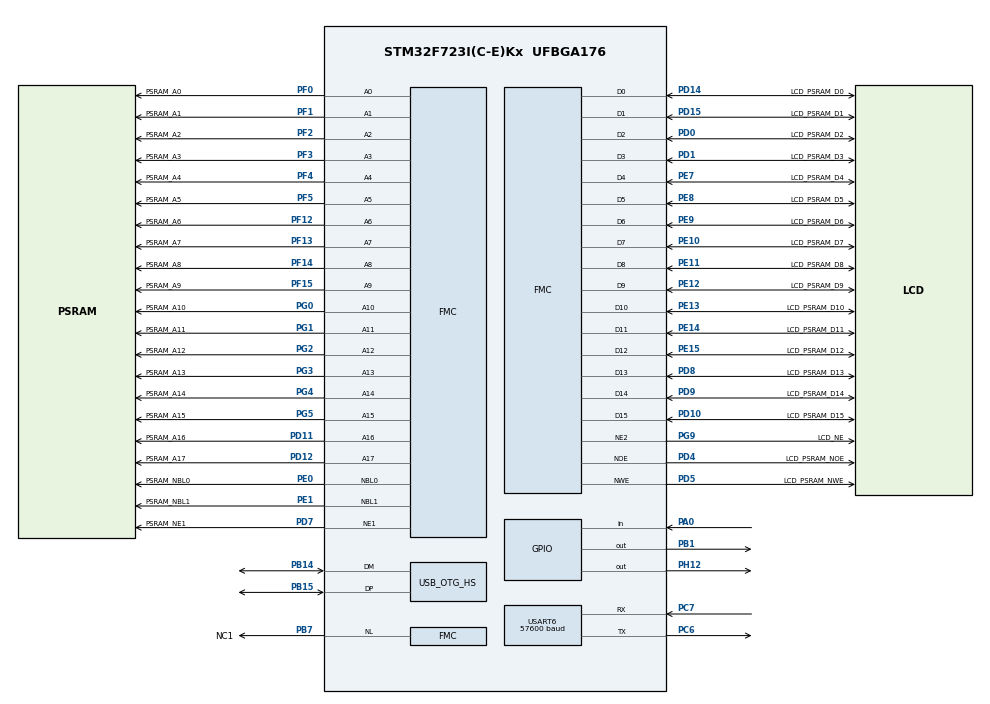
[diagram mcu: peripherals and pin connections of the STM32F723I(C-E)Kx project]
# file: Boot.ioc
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CORTEX_M7.CPU_ICache=Disabled
CORTEX_M7.PREFETCH_ENABLE=0
FMC.WriteOperation1=FMC_WRITE_OPERATION_ENABLE
Mcu.Family=STM32F7
Mcu.Name=STM32F723I(C-E)Kx
Mcu.Package=UFBGA176
NVIC.PriorityGroup=NVIC_PRIORITYGROUP_4
PA0-WKUP.Signal=GPIO_Input
PB1.Signal=GPIO_Output
PB14.Mode=Internal_Phy_Host
PB14.Signal=USB_OTG_HS_DM
PB15.Mode=Internal_Phy_Host
PB15.Signal=USB_OTG_HS_DP
PB7.GPIO_Label=NC1
PB7.Signal=FMC_NL
PC6.Mode=Asynchronous
PC6.Signal=USART6_TX
PC7.Mode=Asynchronous
PC7.Signal=USART6_RX
PD0.GPIO_Label=LCD_PSRAM_D2
PD0.Signal=FMC_D2_DA2
PD1.GPIO_Label=LCD_PSRAM_D3
PD1.Signal=FMC_D3_DA3
PD10.GPIO_Label=LCD_PSRAM_D15
PD10.Signal=FMC_D15_DA15
PD11.GPIO_Label=PSRAM_A16
PD11.Signal=FMC_A16_CLE
PD12.GPIO_Label=PSRAM_A17
PD12.Signal=FMC_A17_ALE
PD14.GPIO_Label=LCD_PSRAM_D0
PD14.Signal=FMC_D0_DA0
PD15.GPIO_Label=LCD_PSRAM_D1
PD15.Signal=FMC_D1_DA1
PD4.GPIO_Label=LCD_PSRAM_NOE
PD4.Signal=FMC_NOE
PD5.GPIO_Label=LCD_PSRAM_NWE
PD5.Signal=FMC_NWE
PD7.GPIO_Label=PSRAM_NE1
PD7.Mode=NorPsramChipSelect1_1
PD7.Signal=FMC_NE1
PD8.GPIO_Label=LCD_PSRAM_D13
PD8.Signal=FMC_D13_DA13
PD9.GPIO_Label=LCD_PSRAM_D14
PD9.Signal=FMC_D14_DA14
PE0.GPIO_Label=PSRAM_NBL0
PE0.Signal=FMC_NBL0
PE1.GPIO_Label=PSRAM_NBL1
PE1.Signal=FMC_NBL1
PE10.GPIO_Label=LCD_PSRAM_D7
PE10.Signal=FMC_D7_DA7
PE11.GPIO_Label=LCD_PSRAM_D8
PE11.Signal=FMC_D8_DA8
PE12.GPIO_Label=LCD_PSRAM_D9
PE12.Signal=FMC_D9_DA9
PE13.GPIO_Label=LCD_PSRAM_D10
PE13.Signal=FMC_D10_DA10
PE14.GPIO_Label=LCD_PSRAM_D11
PE14.Signal=FMC_D11_DA11
PE15.GPIO_Label=LCD_PSRAM_D12
PE15.Signal=FMC_D12_DA12
PE7.GPIO_Label=LCD_PSRAM_D4
PE7.Signal=FMC_D4_DA4
PE8.GPIO_Label=LCD_PSRAM_D5
PE8.Signal=FMC_D5_DA5
PE9.GPIO_Label=LCD_PSRAM_D6
PE9.Signal=FMC_D6_DA6
PF0.GPIO_Label=PSRAM_A0
PF0.Signal=FMC_A0
PF1.GPIO_Label=PSRAM_A1
PF1.Signal=FMC_A1
PF12.GPIO_Label=PSRAM_A6
PF12.Signal=FMC_A6
PF13.GPIO_Label=PSRAM_A7
PF13.Signal=FMC_A7
PF14.GPIO_Label=PSRAM_A8
PF14.Signal=FMC_A8
PF15.GPIO_Label=PSRAM_A9
PF15.Signal=FMC_A9
PF2.GPIO_Label=PSRAM_A2
PF2.Signal=FMC_A2
PF3.GPIO_Label=PSRAM_A3
PF3.Signal=FMC_A3
PF4.GPIO_Label=PSRAM_A4
PF4.Signal=FMC_A4
PF5.GPIO_Label=PSRAM_A5
PF5.Signal=FMC_A5
PG0.GPIO_Label=PSRAM_A10
PG0.Signal=FMC_A10
PG1.GPIO_Label=PSRAM_A11
PG1.Signal=FMC_A11
PG2.GPIO_Label=PSRAM_A12
PG2.Signal=FMC_A12
PG3.GPIO_Label=PSRAM_A13
PG3.Signal=FMC_A13
PG4.GPIO_Label=PSRAM_A14
PG4.Signal=FMC_A14_BA0
PG5.GPIO_Label=PSRAM_A15
PG5.Signal=FMC_A15_BA1
PG9.GPIO_Label=LCD_NE
PG9.Mode=NorPsramChipSelect2_2
PG9.Signal=FMC_NE2
PH0-OSC_IN.Mode=HSE-External-Clock-Source
PH0-OSC_IN.Signal=RCC_OSC_IN
PH1-OSC_OUT.Mode=HSE-External-Clock-Source
PH1-OSC_OUT.Signal=RCC_OSC_OUT
PH12.PinState=GPIO_PIN_SET
PH12.Signal=GPIO_Output
ProjectManager.HeapSize=0x200
ProjectManager.StackSize=0x1000
ProjectManager.TargetToolchain=STM32CubeIDE
RCC.AHBFreq_Value=216000000
RCC.APB1CLKDivider=RCC_HCLK_DIV4
RCC.APB1Freq_Value=54000000
RCC.APB1TimFreq_Value=108000000
RCC.APB2CLKDivider=RCC_HCLK_DIV2
RCC.APB2Freq_Value=108000000
RCC.APB2TimFreq_Value=216000000
RCC.CortexFreq_Value=216000000
RCC.HCLKFreq_Value=216000000
RCC.HSE_VALUE=25000000
RCC.HSI_VALUE=16000000
RCC.LSE_VALUE=32768
RCC.PLLM=25
RCC.PLLN=432
RCC.PLLQ=9
RCC.SYSCLKFreq_VALUE=216000000
RCC.SYSCLKSource=RCC_SYSCLKSOURCE_PLLCLK
RCC.USBFreq_Value=48000000
RCC.VCOOutputFreq_Value=432000000
REXTPHYHS.Mode=Internal_Phy_Host
REXTPHYHS.Signal=USB_OTG_HS_REXTPHYHS
SH.FMC_A0.0=FMC_A0,18b-a1
SH.FMC_A0.1=FMC_A0,A0_2
SH.FMC_A1.0=FMC_A1,18b-a1
SH.FMC_A10.0=FMC_A10,18b-a1
SH.FMC_A11.0=FMC_A11,18b-a1
SH.FMC_A12.0=FMC_A12,18b-a1
SH.FMC_A13.0=FMC_A13,18b-a1
SH.FMC_A14_BA0.0=FMC_A14,18b-a1
SH.FMC_A15_BA1.0=FMC_A15,18b-a1
SH.FMC_A16_CLE.0=FMC_A16,18b-a1
SH.FMC_A17_ALE.0=FMC_A17,18b-a1
SH.FMC_A2.0=FMC_A2,18b-a1
SH.FMC_A3.0=FMC_A3,18b-a1
SH.FMC_A4.0=FMC_A4,18b-a1
SH.FMC_A5.0=FMC_A5,18b-a1
SH.FMC_A6.0=FMC_A6,18b-a1
SH.FMC_A7.0=FMC_A7,18b-a1
SH.FMC_A8.0=FMC_A8,18b-a1
SH.FMC_A9.0=FMC_A9,18b-a1
SH.FMC_D0_DA0.0=FMC_D0,16b-d1
SH.FMC_D0_DA0.1=FMC_D0,16b-d2
SH.FMC_D10_DA10.0=FMC_D10,16b-d1
SH.FMC_D10_DA10.1=FMC_D10,16b-d2
SH.FMC_D11_DA11.0=FMC_D11,16b-d1
SH.FMC_D11_DA11.1=FMC_D11,16b-d2
SH.FMC_D12_DA12.0=FMC_D12,16b-d1
SH.FMC_D12_DA12.1=FMC_D12,16b-d2
SH.FMC_D13_DA13.0=FMC_D13,16b-d1
SH.FMC_D13_DA13.1=FMC_D13,16b-d2
SH.FMC_D14_DA14.0=FMC_D14,16b-d1
SH.FMC_D14_DA14.1=FMC_D14,16b-d2
SH.FMC_D15_DA15.0=FMC_D15,16b-d1
SH.FMC_D15_DA15.1=FMC_D15,16b-d2
SH.FMC_D1_DA1.0=FMC_D1,16b-d1
SH.FMC_D1_DA1.1=FMC_D1,16b-d2
SH.FMC_D2_DA2.0=FMC_D2,16b-d1
SH.FMC_D2_DA2.1=FMC_D2,16b-d2
SH.FMC_D3_DA3.0=FMC_D3,16b-d1
SH.FMC_D3_DA3.1=FMC_D3,16b-d2
SH.FMC_D4_DA4.0=FMC_D4,16b-d1
SH.FMC_D4_DA4.1=FMC_D4,16b-d2
SH.FMC_D5_DA5.0=FMC_D5,16b-d1
SH.FMC_D5_DA5.1=FMC_D5,16b-d2
SH.FMC_D6_DA6.0=FMC_D6,16b-d1
SH.FMC_D6_DA6.1=FMC_D6,16b-d2
SH.FMC_D7_DA7.0=FMC_D7,16b-d1
SH.FMC_D7_DA7.1=FMC_D7,16b-d2
SH.FMC_D8_DA8.0=FMC_D8,16b-d1
SH.FMC_D8_DA8.1=FMC_D8,16b-d2
SH.FMC_D9_DA9.0=FMC_D9,16b-d1
SH.FMC_D9_DA9.1=FMC_D9,16b-d2
SH.FMC_NBL0.0=FMC_NBL0,2ByteEnable1
SH.FMC_NBL1.0=FMC_NBL1,2ByteEnable1
SH.FMC_NL.0=FMC_NL,AddressValid1
SH.FMC_NOE.0=FMC_NOE,Psram1
SH.FMC_NOE.1=FMC_NOE,Lcd2
SH.FMC_NWE.0=FMC_NWE,Psram1
SH.FMC_NWE.1=FMC_NWE,Lcd2
USART6.BaudRate=57600
USART6.VirtualMode-Asynchronous=VM_ASYNC
USB_OTG_HS.VirtualMode=Int_Phy_Host
board=STM32F723E-DISCO

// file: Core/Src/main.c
/* USER CODE BEGIN Header */
/**
  ******************************************************************************
  * @file           : main.c
  * @brief          : Main program body
  ******************************************************************************
  * @attention
  *
  * Copyright (c) 2026 STMicroelectronics.
  * All rights reserved.
  *
  * This software is licensed under terms that can be found in the LICENSE file
  * in the root directory of this software component.
  * If no LICENSE file comes with this software, it is provided AS-IS.
  *
  ******************************************************************************
  */
/* USER CODE END Header */
#include "main.h"

/* USER CODE BEGIN Includes */
#include "app.h"
/* USER CODE END Includes */

HCD_HandleTypeDef hhcd_USB_OTG_HS;

SRAM_HandleTypeDef hsram1;
SRAM_HandleTypeDef hsram2;

void SystemClock_Config(void);
static void MX_GPIO_Init(void);
static void MX_USART6_UART_Init(void);

int main(void)
{

  /* MCU Configuration--------------------------------------------------------*/

  /* Reset of all peripherals, Initializes the Flash interface and the Systick. */
  HAL_Init();

  /* Configure the system clock */
  SystemClock_Config();

  /* Initialize all configured peripherals */
  MX_GPIO_Init();
  MX_USART6_UART_Init();
  /* USER CODE BEGIN 2 */
  /* Initialize the USB HS clock and GPIO pins. */
  HCD_HandleTypeDef usbHandle;
  usbHandle.Instance = USB_OTG_HS;
  HAL_HCD_MspInit(&usbHandle);
  /* Initialize the bootloader application. */
  AppInit();
  /* USER CODE END 2 */

  /* Infinite loop */
  /* USER CODE BEGIN WHILE */
  while (1)
  {
    /* Run the bootloader application. */
    AppTask();
    /* USER CODE END WHILE */

  }
}

void SystemClock_Config(void)
{
  LL_FLASH_SetLatency(LL_FLASH_LATENCY_7);
  while(LL_FLASH_GetLatency()!= LL_FLASH_LATENCY_7)
  {
  }
  LL_PWR_SetRegulVoltageScaling(LL_PWR_REGU_VOLTAGE_SCALE1);
  LL_PWR_EnableOverDriveMode();
  LL_RCC_HSE_EnableBypass();
  LL_RCC_HSE_Enable();

   /* Wait till HSE is ready */
  while(LL_RCC_HSE_IsReady() != 1)
  {

  }
  LL_RCC_PLL_ConfigDomain_SYS(LL_RCC_PLLSOURCE_HSE, LL_RCC_PLLM_DIV_25, 432, LL_RCC_PLLP_DIV_2);
  LL_RCC_PLL_ConfigDomain_48M(LL_RCC_PLLSOURCE_HSE, LL_RCC_PLLM_DIV_25, 432, LL_RCC_PLLQ_DIV_9);
  LL_RCC_PLL_Enable();

   /* Wait till PLL is ready */
  while(LL_RCC_PLL_IsReady() != 1)
  {

  }
  while (LL_PWR_IsActiveFlag_VOS() == 0)
  {
  }
  LL_RCC_SetAHBPrescaler(LL_RCC_SYSCLK_DIV_1);
  LL_RCC_SetAPB1Prescaler(LL_RCC_APB1_DIV_4);
  LL_RCC_SetAPB2Prescaler(LL_RCC_APB2_DIV_2);
  LL_RCC_SetSysClkSource(LL_RCC_SYS_CLKSOURCE_PLL);

   /* Wait till System clock is ready */
  while(LL_RCC_GetSysClkSource() != LL_RCC_SYS_CLKSOURCE_STATUS_PLL)
  {

  }
  LL_SetSystemCoreClock(216000000);

   /* Update the time base */
  if (HAL_InitTick (TICK_INT_PRIORITY) != HAL_OK)
  {
    Error_Handler();
  }

   /* Set Timers Clock Prescalers */
  LL_RCC_SetTIMPrescaler(LL_RCC_TIM_PRESCALER_TWICE);
}

static void MX_USART6_UART_Init(void)
{

  LL_USART_InitTypeDef USART_InitStruct = {0};

  LL_GPIO_InitTypeDef GPIO_InitStruct = {0};

  LL_RCC_SetUSARTClockSource(LL_RCC_USART6_CLKSOURCE_PCLK2);

  /* Peripheral clock enable */
  LL_APB2_GRP1_EnableClock(LL_APB2_GRP1_PERIPH_USART6);

  LL_AHB1_GRP1_EnableClock(LL_AHB1_GRP1_PERIPH_GPIOC);
  /**USART6 GPIO Configuration
  PC7   ------> USART6_RX
  PC6   ------> USART6_TX
  */
  GPIO_InitStruct.Pin = LL_GPIO_PIN_7;
  GPIO_InitStruct.Mode = LL_GPIO_MODE_ALTERNATE;
  GPIO_InitStruct.Speed = LL_GPIO_SPEED_FREQ_VERY_HIGH;
  GPIO_InitStruct.OutputType = LL_GPIO_OUTPUT_PUSHPULL;
  GPIO_InitStruct.Pull = LL_GPIO_PULL_NO;
  GPIO_InitStruct.Alternate = LL_GPIO_AF_8;
  LL_GPIO_Init(GPIOC, &GPIO_InitStruct);

  GPIO_InitStruct.Pin = LL_GPIO_PIN_6;
  GPIO_InitStruct.Mode = LL_GPIO_MODE_ALTERNATE;
  GPIO_InitStruct.Speed = LL_GPIO_SPEED_FREQ_VERY_HIGH;
  GPIO_InitStruct.OutputType = LL_GPIO_OUTPUT_PUSHPULL;
  GPIO_InitStruct.Pull = LL_GPIO_PULL_NO;
  GPIO_InitStruct.Alternate = LL_GPIO_AF_8;
  LL_GPIO_Init(GPIOC, &GPIO_InitStruct);

  /* USER CODE BEGIN USART6_Init 1 */
  /* Note that the USART initialization that follows here is don't care. It is
   * reconfigured upon bootloader initialization with function Rs232Init().
   */
  /* USER CODE END USART6_Init 1 */
  USART_InitStruct.BaudRate = 57600;
  USART_InitStruct.DataWidth = LL_USART_DATAWIDTH_8B;
  USART_InitStruct.StopBits = LL_USART_STOPBITS_1;
  USART_InitStruct.Parity = LL_USART_PARITY_NONE;
  USART_InitStruct.TransferDirection = LL_USART_DIRECTION_TX_RX;
  USART_InitStruct.HardwareFlowControl = LL_USART_HWCONTROL_NONE;
  USART_InitStruct.OverSampling = LL_USART_OVERSAMPLING_16;
  LL_USART_Init(USART6, &USART_InitStruct);
  LL_USART_ConfigAsyncMode(USART6);
  LL_USART_Enable(USART6);

}

void MX_USB_OTG_HS_HCD_Init(void)
{

  /* USER CODE BEGIN USB_OTG_HS_Init 0 */
  /* Note that the USB initialization that follows here is not actually used. The USB
   * disk module handles its initialization.
   */
  /* USER CODE END USB_OTG_HS_Init 0 */

  hhcd_USB_OTG_HS.Instance = USB_OTG_HS;
  hhcd_USB_OTG_HS.Init.Host_channels = 16;
  hhcd_USB_OTG_HS.Init.speed = USB_OTG_SPEED_HIGH;
  hhcd_USB_OTG_HS.Init.dma_enable = DISABLE;
  hhcd_USB_OTG_HS.Init.phy_itface = USB_OTG_HS_EMBEDDED_PHY;
  hhcd_USB_OTG_HS.Init.Sof_enable = DISABLE;
  hhcd_USB_OTG_HS.Init.low_power_enable = DISABLE;
  hhcd_USB_OTG_HS.Init.vbus_sensing_enable = DISABLE;
  hhcd_USB_OTG_HS.Init.use_external_vbus = ENABLE;
  if (HAL_HCD_Init(&hhcd_USB_OTG_HS) != HAL_OK)
  {
    Error_Handler();
  }

}

/* FMC initialization function */
void MX_FMC_Init(void)
{

  /* USER CODE BEGIN FMC_Init 0 */
  /* Note that the FMC initialization that follows here is not actually used. The display
   * module handles its initialization.
   */
  /* USER CODE END FMC_Init 0 */

  FMC_NORSRAM_TimingTypeDef Timing = {0};

  /** Perform the SRAM1 memory initialization sequence
  */
  hsram1.Instance = FMC_NORSRAM_DEVICE;
  hsram1.Extended = FMC_NORSRAM_EXTENDED_DEVICE;
  /* hsram1.Init */
  hsram1.Init.NSBank = FMC_NORSRAM_BANK1;
  hsram1.Init.DataAddressMux = FMC_DATA_ADDRESS_MUX_DISABLE;
  hsram1.Init.MemoryType = FMC_MEMORY_TYPE_PSRAM;
  hsram1.Init.MemoryDataWidth = FMC_NORSRAM_MEM_BUS_WIDTH_16;
  hsram1.Init.BurstAccessMode = FMC_BURST_ACCESS_MODE_DISABLE;
  hsram1.Init.WaitSignalPolarity = FMC_WAIT_SIGNAL_POLARITY_LOW;
  hsram1.Init.WaitSignalActive = FMC_WAIT_TIMING_BEFORE_WS;
  hsram1.Init.WriteOperation = FMC_WRITE_OPERATION_ENABLE;
  hsram1.Init.WaitSignal = FMC_WAIT_SIGNAL_DISABLE;
  hsram1.Init.ExtendedMode = FMC_EXTENDED_MODE_DISABLE;
  hsram1.Init.AsynchronousWait = FMC_ASYNCHRONOUS_WAIT_DISABLE;
  hsram1.Init.WriteBurst = FMC_WRITE_BURST_DISABLE;
  hsram1.Init.ContinuousClock = FMC_CONTINUOUS_CLOCK_SYNC_ONLY;
  hsram1.Init.WriteFifo = FMC_WRITE_FIFO_ENABLE;
  hsram1.Init.PageSize = FMC_PAGE_SIZE_NONE;
  /* Timing */
  Timing.AddressSetupTime = 15;
  Timing.AddressHoldTime = 15;
  Timing.DataSetupTime = 255;
  Timing.BusTurnAroundDuration = 15;
  Timing.CLKDivision = 16;
  Timing.DataLatency = 17;
  Timing.AccessMode = FMC_ACCESS_MODE_A;
  /* ExtTiming */

  if (HAL_SRAM_Init(&hsram1, &Timing, NULL) != HAL_OK)
  {
    Error_Handler( );
  }

  /** Perform the SRAM2 memory initialization sequence
  */
  hsram2.Instance = FMC_NORSRAM_DEVICE;
  hsram2.Extended = FMC_NORSRAM_EXTENDED_DEVICE;
  /* hsram2.Init */
  hsram2.Init.NSBank = FMC_NORSRAM_BANK2;
  hsram2.Init.DataAddressMux = FMC_DATA_ADDRESS_MUX_DISABLE;
  hsram2.Init.MemoryType = FMC_MEMORY_TYPE_SRAM;
  hsram2.Init.MemoryDataWidth = FMC_NORSRAM_MEM_BUS_WIDTH_16;
  hsram2.Init.BurstAccessMode = FMC_BURST_ACCESS_MODE_DISABLE;
  hsram2.Init.WaitSignalPolarity = FMC_WAIT_SIGNAL_POLARITY_LOW;
  hsram2.Init.WaitSignalActive = FMC_WAIT_TIMING_BEFORE_WS;
  hsram2.Init.WriteOperation = FMC_WRITE_OPERATION_ENABLE;
  hsram2.Init.WaitSignal = FMC_WAIT_SIGNAL_DISABLE;
  hsram2.Init.ExtendedMode = FMC_EXTENDED_MODE_DISABLE;
  hsram2.Init.AsynchronousWait = FMC_ASYNCHRONOUS_WAIT_DISABLE;
  hsram2.Init.WriteBurst = FMC_WRITE_BURST_DISABLE;
  hsram2.Init.ContinuousClock = FMC_CONTINUOUS_CLOCK_SYNC_ONLY;
  hsram2.Init.WriteFifo = FMC_WRITE_FIFO_ENABLE;
  hsram2.Init.PageSize = FMC_PAGE_SIZE_NONE;
  /* Timing */
  Timing.AddressSetupTime = 15;
  Timing.AddressHoldTime = 15;
  Timing.DataSetupTime = 255;
  Timing.BusTurnAroundDuration = 15;
  Timing.CLKDivision = 16;
  Timing.DataLatency = 17;
  Timing.AccessMode = FMC_ACCESS_MODE_A;
  /* ExtTiming */

  if (HAL_SRAM_Init(&hsram2, &Timing, NULL) != HAL_OK)
  {
    Error_Handler( );
  }

}

static void MX_GPIO_Init(void)
{
  LL_GPIO_InitTypeDef GPIO_InitStruct = {0};

  /* GPIO Ports Clock Enable */
  LL_AHB1_GRP1_EnableClock(LL_AHB1_GRP1_PERIPH_GPIOE);
  LL_AHB1_GRP1_EnableClock(LL_AHB1_GRP1_PERIPH_GPIOD);
  LL_AHB1_GRP1_EnableClock(LL_AHB1_GRP1_PERIPH_GPIOB);
  LL_AHB1_GRP1_EnableClock(LL_AHB1_GRP1_PERIPH_GPIOG);
  LL_AHB1_GRP1_EnableClock(LL_AHB1_GRP1_PERIPH_GPIOF);
  LL_AHB1_GRP1_EnableClock(LL_AHB1_GRP1_PERIPH_GPIOH);
  LL_AHB1_GRP1_EnableClock(LL_AHB1_GRP1_PERIPH_GPIOC);
  LL_AHB1_GRP1_EnableClock(LL_AHB1_GRP1_PERIPH_GPIOA);

  /**/
  LL_GPIO_SetOutputPin(GPIOH, LL_GPIO_PIN_12);

  /**/
  LL_GPIO_ResetOutputPin(GPIOB, LL_GPIO_PIN_1);

  /**/
  GPIO_InitStruct.Pin = LL_GPIO_PIN_12;
  GPIO_InitStruct.Mode = LL_GPIO_MODE_OUTPUT;
  GPIO_InitStruct.Speed = LL_GPIO_SPEED_FREQ_LOW;
  GPIO_InitStruct.OutputType = LL_GPIO_OUTPUT_PUSHPULL;
  GPIO_InitStruct.Pull = LL_GPIO_PULL_NO;
  LL_GPIO_Init(GPIOH, &GPIO_InitStruct);

  /**/
  GPIO_InitStruct.Pin = LL_GPIO_PIN_0;
  GPIO_InitStruct.Mode = LL_GPIO_MODE_INPUT;
  GPIO_InitStruct.Pull = LL_GPIO_PULL_NO;
  LL_GPIO_Init(GPIOA, &GPIO_InitStruct);

  /**/
  GPIO_InitStruct.Pin = LL_GPIO_PIN_1;
  GPIO_InitStruct.Mode = LL_GPIO_MODE_OUTPUT;
  GPIO_InitStruct.Speed = LL_GPIO_SPEED_FREQ_LOW;
  GPIO_InitStruct.OutputType = LL_GPIO_OUTPUT_PUSHPULL;
  GPIO_InitStruct.Pull = LL_GPIO_PULL_NO;
  LL_GPIO_Init(GPIOB, &GPIO_InitStruct);

}

void Error_Handler(void)
{
  __disable_irq();
  while (1)
  {
  }
}
